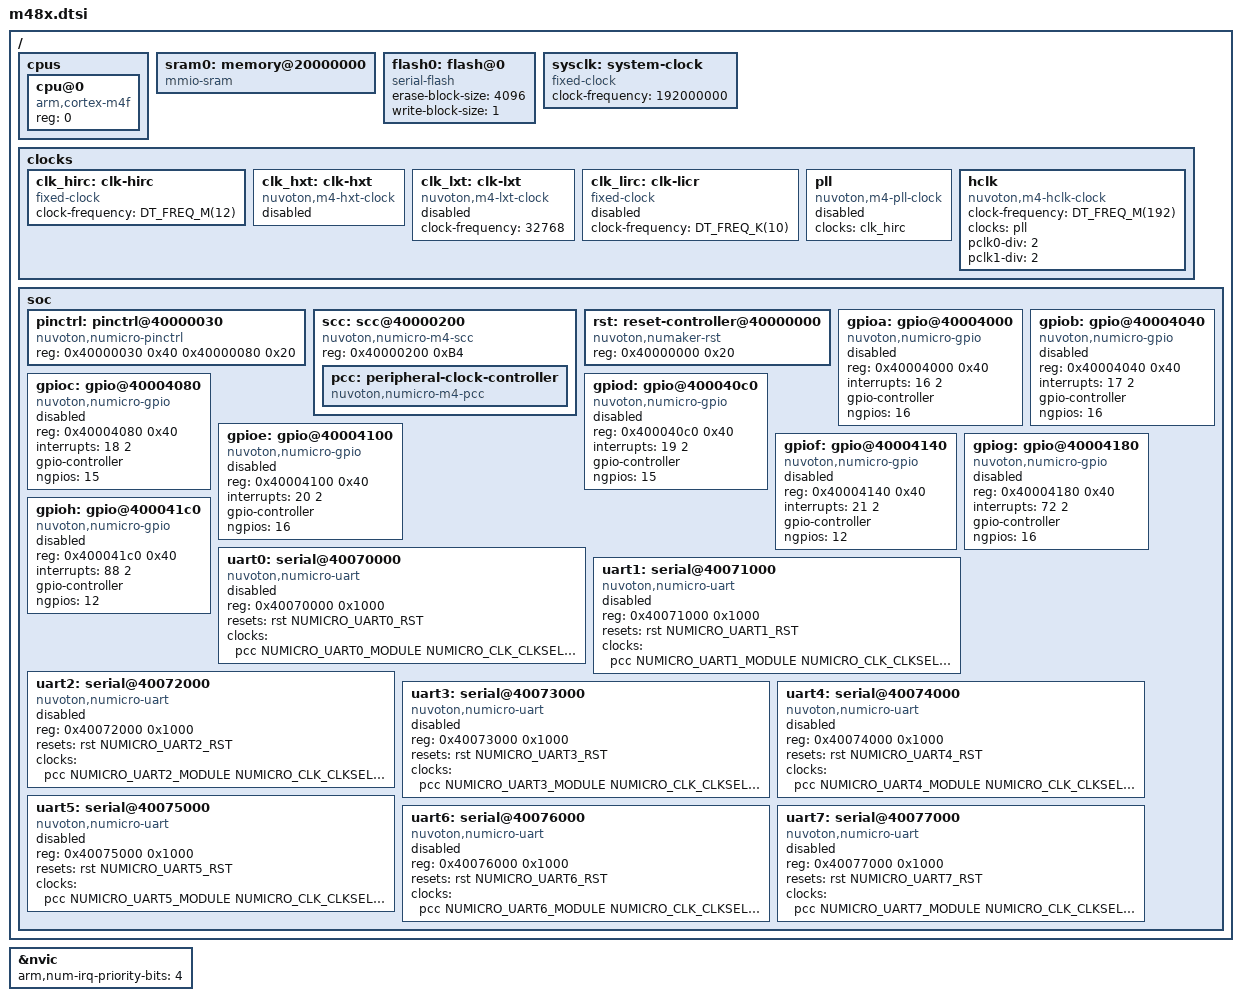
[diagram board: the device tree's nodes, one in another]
/*
 * Copyright (c) 2020 Linumiz
 *
 * SPDX-License-Identifier: Apache-2.0
 */

#include <arm/armv7-m.dtsi>
#include <mem.h>
#include <zephyr/dt-bindings/gpio/gpio.h>
#include <zephyr/dt-bindings/reset/numicro_m48x_reset.h>
#include <zephyr/dt-bindings/clock/numicro_m48x_clock.h>
#include <freq.h>

/ {
	cpus {
		#address-cells = <1>;
		#size-cells = <0>;

		cpu@0 {
			device_type = "cpu";
			compatible = "arm,cortex-m4f";
			reg = <0>;
		};
	};

	sram0: memory@20000000 {
		compatible = "mmio-sram";
	};

	flash0: flash@0 {
		compatible = "serial-flash";
		erase-block-size = <4096>;
		write-block-size = <1>;
	};

	sysclk: system-clock {
		compatible = "fixed-clock";
		clock-frequency = <192000000>;
		#clock-cells = <0>;
	};

	clocks {
		#address-cells = <1>;
		#size-cells = <0>;

		clk_hirc: clk-hirc {
			#clock-cells = <0>;
			compatible = "fixed-clock";
			clock-frequency = <DT_FREQ_M(12)>;
			status = "okay";
		};

		clk_hxt: clk-hxt {
			#clock-cells = <0>;
			compatible = "nuvoton,m4-hxt-clock";
			status = "disabled";
		};

		clk_lxt: clk-lxt {
			#clock-cells = <0>;
			compatible = "nuvoton,m4-lxt-clock";
			clock-frequency = <32768>;
			status = "disabled";
		};

		clk_lirc: clk-licr {
			#clock-cells = <0>;
			compatible = "fixed-clock";
			clock-frequency = <DT_FREQ_K(10)>;
			status = "disabled";
		};

		pll: pll {
			#clock-cells = <0>;
			compatible = "nuvoton,m4-pll-clock";
			clocks = <&clk_hirc>;
			status = "disabled";
		};

		hclk: hclk {
			#clock-cells = <0>;
			compatible = "nuvoton,m4-hclk-clock";
			clock-frequency = <DT_FREQ_M(192)>;
			clocks = <&pll>;
			pclk0-div = <2>;
			pclk1-div = <2>;
		};
	};

	soc {
		pinctrl: pinctrl@40000030 {
			compatible = "nuvoton,numicro-pinctrl";
			reg = <0x40000030 0x40
			       0x40000080 0x20>;
			reg-names = "mfp", "mfos";
			status = "okay";
		};

		scc: scc@40000200 {
			compatible = "nuvoton,numicro-m4-scc";
			#clock-cells = <0>;
			reg = <0x40000200 0xB4>;
			status = "okay";

			pcc: peripheral-clock-controller {
				compatible = "nuvoton,numicro-m4-pcc";
				#clock-cells = <3>;
			};
		};
		
		rst: reset-controller@40000000 {
			compatible = "nuvoton,numaker-rst";
			reg = <0x40000000 0x20>;
			#reset-cells = <1>;
			status = "okay";

		};

		gpioa: gpio@40004000 {
			compatible = "nuvoton,numicro-gpio";
			reg = <0x40004000 0x40>;
			status = "disabled";
			interrupts = <16 2>;
			gpio-controller;
			#gpio-cells = <2>;
			ngpios = <16>;
		};

		gpiob: gpio@40004040 {
			compatible = "nuvoton,numicro-gpio";
			reg = <0x40004040 0x40>;
			status = "disabled";
			interrupts = <17 2>;
			gpio-controller;
			#gpio-cells = <2>;
			ngpios = <16>;
		};

		gpioc: gpio@40004080 {
			compatible = "nuvoton,numicro-gpio";
			reg = <0x40004080 0x40>;
			status = "disabled";
			interrupts = <18 2>;
			gpio-controller;
			#gpio-cells = <2>;
			ngpios = <15>;
		};

		gpiod: gpio@400040c0 {
			compatible = "nuvoton,numicro-gpio";
			reg = <0x400040c0 0x40>;
			status = "disabled";
			interrupts = <19 2>;
			gpio-controller;
			#gpio-cells = <2>;
			ngpios = <15>;
		};

		gpioe: gpio@40004100 {
			compatible = "nuvoton,numicro-gpio";
			reg = <0x40004100 0x40>;
			status = "disabled";
			interrupts = <20 2>;
			gpio-controller;
			#gpio-cells = <2>;
			ngpios = <16>;
		};

		gpiof: gpio@40004140 {
			compatible = "nuvoton,numicro-gpio";
			reg = <0x40004140 0x40>;
			status = "disabled";
			interrupts = <21 2>;
			gpio-controller;
			#gpio-cells = <2>;
			ngpios = <12>;
		};

		gpiog: gpio@40004180 {
			compatible = "nuvoton,numicro-gpio";
			reg = <0x40004180 0x40>;
			status = "disabled";
			interrupts = <72 2>;
			gpio-controller;
			#gpio-cells = <2>;
			ngpios = <16>;
		};

		gpioh: gpio@400041c0 {
			compatible = "nuvoton,numicro-gpio";
			reg = <0x400041c0 0x40>;
			status = "disabled";
			interrupts = <88 2>;
			gpio-controller;
			#gpio-cells = <2>;
			ngpios = <12>;
		};

		uart0: serial@40070000 {
			compatible = "nuvoton,numicro-uart";
			reg = <0x40070000 0x1000>;
			resets = <&rst NUMICRO_UART0_RST>;
			clocks = <&pcc NUMICRO_UART0_MODULE NUMICRO_CLK_CLKSEL1_UART0SEL_HIRC NUMICRO_CLK_CLKDIV0_UART0(1)>;
			status = "disabled";
		};

		uart1: serial@40071000 {
			compatible = "nuvoton,numicro-uart";
			reg = <0x40071000 0x1000>;
			resets = <&rst NUMICRO_UART1_RST>;
			clocks = <&pcc NUMICRO_UART1_MODULE NUMICRO_CLK_CLKSEL1_UART1SEL_HIRC NUMICRO_CLK_CLKDIV0_UART1(1)>;
			status = "disabled";
		};

		uart2: serial@40072000 {
			compatible = "nuvoton,numicro-uart";
			reg = <0x40072000 0x1000>;
			resets = <&rst NUMICRO_UART2_RST>;
			clocks = <&pcc NUMICRO_UART2_MODULE NUMICRO_CLK_CLKSEL3_UART2SEL_HIRC NUMICRO_CLK_CLKDIV4_UART2(1)>;
			status = "disabled";
		};

		uart3: serial@40073000 {
			compatible = "nuvoton,numicro-uart";
			reg = <0x40073000 0x1000>;
			resets = <&rst NUMICRO_UART3_RST>;
			clocks = <&pcc NUMICRO_UART3_MODULE NUMICRO_CLK_CLKSEL3_UART3SEL_HIRC NUMICRO_CLK_CLKDIV4_UART3(1)>;
			status = "disabled";
		};

		uart4: serial@40074000 {
			compatible = "nuvoton,numicro-uart";
			reg = <0x40074000 0x1000>;
			resets = <&rst NUMICRO_UART4_RST>;
			clocks = <&pcc NUMICRO_UART4_MODULE NUMICRO_CLK_CLKSEL3_UART4SEL_HIRC NUMICRO_CLK_CLKDIV4_UART4(1)>;
			status = "disabled";
		};

		uart5: serial@40075000 {
			compatible = "nuvoton,numicro-uart";
			reg = <0x40075000 0x1000>;
			resets = <&rst NUMICRO_UART5_RST>;
			clocks = <&pcc NUMICRO_UART5_MODULE NUMICRO_CLK_CLKSEL3_UART5SEL_HIRC NUMICRO_CLK_CLKDIV4_UART5(1)>;
			status = "disabled";
		};

		uart6: serial@40076000 {
			compatible = "nuvoton,numicro-uart";
			reg = <0x40076000 0x1000>;
			resets = <&rst NUMICRO_UART6_RST>;
			clocks = <&pcc NUMICRO_UART6_MODULE NUMICRO_CLK_CLKSEL3_UART6SEL_HIRC NUMICRO_CLK_CLKDIV4_UART6(1)>;
			status = "disabled";
		};

		uart7: serial@40077000 {
			compatible = "nuvoton,numicro-uart";
			reg = <0x40077000 0x1000>;
			resets = <&rst NUMICRO_UART7_RST>;
			clocks = <&pcc NUMICRO_UART7_MODULE NUMICRO_CLK_CLKSEL3_UART7SEL_HIRC NUMICRO_CLK_CLKDIV4_UART7(1)>;
			status = "disabled";
		};
	};
};

&nvic {
	arm,num-irq-priority-bits = <4>;
};
